# cslr_aif register map
Vendor: Texas Instruments
Registers are 32-bit, access per field, reset 0x0 unless marked. A register's access mark holds for its fields unless they carry their own. Offsets are as the file gives them; [hi:lo] are bit positions; {n}, {i} and the like mark numbered series; 'fields as' and 'values as' point back to an identical list.

## AIF (part 5 of 5) — High-speed interface for BTS antenna data
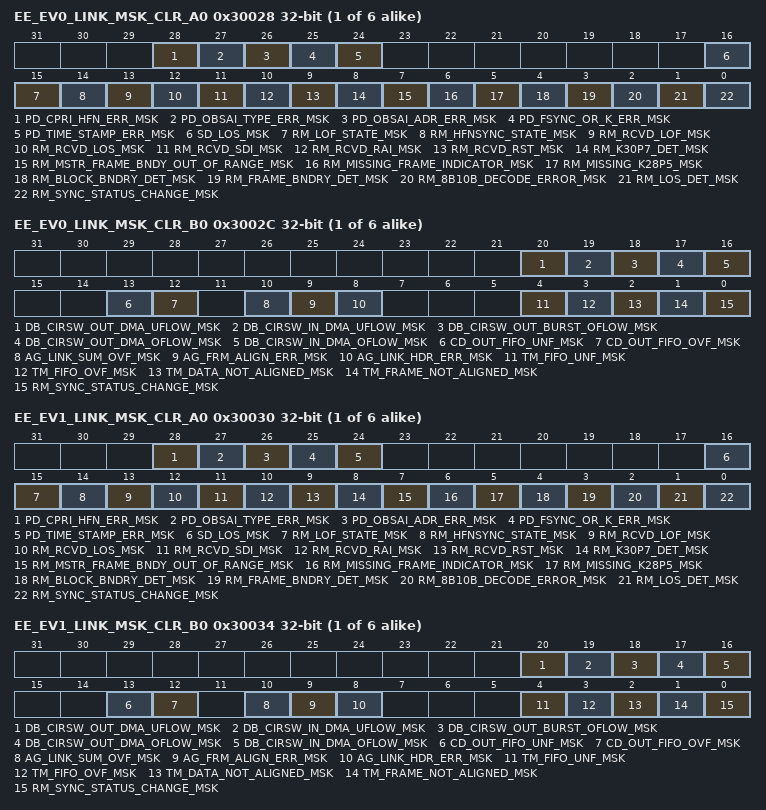
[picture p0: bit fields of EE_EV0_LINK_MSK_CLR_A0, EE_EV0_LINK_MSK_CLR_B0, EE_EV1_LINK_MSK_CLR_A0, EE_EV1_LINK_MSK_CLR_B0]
{0x30028+0x800*i} EE_EV0_LINK_MSK_CLR_A{i} (i=0..5) — Event 0 Link Interrupt Mask Clear Reg A
  [28] PD_CPRI_HFN_ERR_MSK rw — Mask for associated bit in the EE_EV0_LINK_ISM_A register. Writing this bit to a 1 clears the mask to 0 to disable the associated error/alarm. Reading this register returns the value of the mask bit.
  [27] PD_OBSAI_TYPE_ERR_MSK rw — Mask for associated bit in the EE_EV0_LINK_ISM_A register. Writing this bit to a 1 clears the mask to 0 to disable the associated error/alarm. Reading this register returns the value of the mask bit.
  [26] PD_OBSAI_ADR_ERR_MSK rw — Mask for associated bit in the EE_EV0_LINK_ISM_A register. Writing this bit to a 1 clears the mask to 0 to disable the associated error/alarm. Reading this register returns the value of the mask bit.
  [25] PD_FSYNC_OR_K_ERR_MSK rw — Mask for associated bit in the EE_EV0_LINK_ISM_A register. Writing this bit to a 1 clears the mask to 0 to disable the associated error/alarm. Reading this register returns the value of the mask bit.
  [24] PD_TIME_STAMP_ERR_MSK rw — Mask for associated bit in the EE_EV0_LINK_ISM_A register. Writing this bit to a 1 clears the mask to 0 to disable the associated error/alarm. Reading this register returns the value of the mask bit.
  [16] SD_LOS_MSK rw — Mask for associated bit in the EE_EV0_LINK_ISM_A register. Writing this bit to a 1 clears the mask to 0 to disable the associated error/alarm. Reading this register returns the value of the mask bit.
  [15] RM_LOF_STATE_MSK rw — Mask for associated bit in the EE_EV0_LINK_ISM_A register. Writing this bit to a 1 clears the mask to 0 to disable the associated error/alarm. Reading this register returns the value of the mask bit.
  [14] RM_HFNSYNC_STATE_MSK rw — Mask for associated bit in the EE_EV0_LINK_ISM_A register. Writing this bit to a 1 clears the mask to 0 to disable the associated error/alarm. Reading this register returns the value of the mask bit.
  [13] RM_RCVD_LOF_MSK rw — Mask for associated bit in the EE_EV0_LINK_ISM_A register. Writing this bit to a 1 clears the mask to 0 to disable the associated error/alarm. Reading this register returns the value of the mask bit.
  [12] RM_RCVD_LOS_MSK rw — Mask for associated bit in the EE_EV0_LINK_ISM_A register. Writing this bit to a 1 clears the mask to 0 to disable the associated error/alarm. Reading this register returns the value of the mask bit.
  [11] RM_RCVD_SDI_MSK rw — Mask for associated bit in the EE_EV0_LINK_ISM_A register. Writing this bit to a 1 clears the mask to 0 to disable the associated error/alarm. Reading this register returns the value of the mask bit.
  [10] RM_RCVD_RAI_MSK rw — Mask for associated bit in the EE_EV0_LINK_ISM_A register. Writing this bit to a 1 clears the mask to 0 to disable the associated error/alarm. Reading this register returns the value of the mask bit.
  [9] RM_RCVD_RST_MSK rw — Mask for associated bit in the EE_EV0_LINK_ISM_A register. Writing this bit to a 1 clears the mask to 0 to disable the associated error/alarm. Reading this register returns the value of the mask bit.
  [8] RM_K30P7_DET_MSK rw — Mask for associated bit in the EE_EV0_LINK_ISM_A register. Writing this bit to a 1 clears the mask to 0 to disable the associated error/alarm. Reading this register returns the value of the mask bit.
  [7] RM_MSTR_FRAME_BNDY_OUT_OF_RANGE_MSK rw — Mask for associated bit in the EE_EV0_LINK_ISM_A register. Writing this bit to a 1 clears the mask to 0 to disable the associated error/alarm. Reading this register returns the value of the mask bit.
  [6] RM_MISSING_FRAME_INDICATOR_MSK rw — Mask for associated bit in the EE_EV0_LINK_ISM_A register. Writing this bit to a 1 clears the mask to 0 to disable the associated error/alarm. Reading this register returns the value of the mask bit.
  [5] RM_MISSING_K28P5_MSK rw — Mask for associated bit in the EE_EV0_LINK_ISM_A register. Writing this bit to a 1 clears the mask to 0 to disable the associated error/alarm. Reading this register returns the value of the mask bit.
  [4] RM_BLOCK_BNDRY_DET_MSK rw — Mask for associated bit in the EE_EV0_LINK_ISM_A register. Writing this bit to a 1 clears the mask to 0 to disable the associated error/alarm. Reading this register returns the value of the mask bit.
  [3] RM_FRAME_BNDRY_DET_MSK rw — Mask for associated bit in the EE_EV0_LINK_ISM_A register. Writing this bit to a 1 clears the mask to 0 to disable the associated error/alarm. Reading this register returns the value of the mask bit.
  [2] RM_8B10B_DECODE_ERROR_MSK rw — Mask for associated bit in the EE_EV0_LINK_ISM_A register. Writing this bit to a 1 clears the mask to 0 to disable the associated error/alarm. Reading this register returns the value of the mask bit.
  [1] RM_LOS_DET_MSK rw — Mask for associated bit in the EE_EV0_LINK_ISM_A register. Writing this bit to a 1 clears the mask to 0 to disable the associated error/alarm. Reading this register returns the value of the mask bit.
  [0] RM_SYNC_STATUS_CHANGE_MSK rw — Mask for associated bit in the EE_EV0_LINK_ISM_A register. Writing this bit to a 1 clears the mask to 0 to disable the associated error/alarm. Reading this register returns the value of the mask bit.
{0x3002C+0x800*i} EE_EV0_LINK_MSK_CLR_B{i} (i=0..5) — Event 0 Link Interrupt Mask Clear Reg B
  [20] DB_CIRSW_OUT_DMA_UFLOW_MSK rw — Mask for associated bit in the EE_EV0_LINK_ISM_B register. Writing this bit to a 1 clears the mask to 0 to disable the associated error/alarm. Reading this register returns the value of the mask bit.
  [19] DB_CIRSW_IN_DMA_UFLOW_MSK rw — Mask for associated bit in the EE_EV0_LINK_ISM_B register. Writing this bit to a 1 clears the mask to 0 to disable the associated error/alarm. Reading this register returns the value of the mask bit.
  [18] DB_CIRSW_OUT_BURST_OFLOW_MSK rw — Mask for associated bit in the EE_EV0_LINK_ISM_B register. Writing this bit to a 1 clears the mask to 0 to disable the associated error/alarm. Reading this register returns the value of the mask bit.
  [17] DB_CIRSW_OUT_DMA_OFLOW_MSK rw — Mask for associated bit in the EE_EV0_LINK_ISM_B register. Writing this bit to a 1 clears the mask to 0 to disable the associated error/alarm. Reading this register returns the value of the mask bit.
  [16] DB_CIRSW_IN_DMA_OFLOW_MSK rw — Mask for associated bit in the EE_EV0_LINK_ISM_B register. Writing this bit to a 1 clears the mask to 0 to disable the associated error/alarm. Reading this register returns the value of the mask bit.
  [13] CD_OUT_FIFO_UNF_MSK rw — Mask for associated bit in the EE_EV0_LINK_ISM_B register. Writing this bit to a 1 clears the mask to 0 to disable the associated error/alarm. Reading this register returns the value of the mask bit.
  [12] CD_OUT_FIFO_OVF_MSK rw — Mask for associated bit in the EE_EV0_LINK_ISM_B register. Writing this bit to a 1 clears the mask to 0 to disable the associated error/alarm. Reading this register returns the value of the mask bit.
  [10] AG_LINK_SUM_OVF_MSK rw — Mask for associated bit in the EE_EV0_LINK_ISM_B register. Writing this bit to a 1 clears the mask to 0 to disable the associated error/alarm. Reading this register returns the value of the mask bit.
  [9] AG_FRM_ALIGN_ERR_MSK rw — Mask for associated bit in the EE_EV0_LINK_ISM_B register. Writing this bit to a 1 clears the mask to 0 to disable the associated error/alarm. Reading this register returns the value of the mask bit.
  [8] AG_LINK_HDR_ERR_MSK rw — Mask for associated bit in the EE_EV0_LINK_ISM_B register. Writing this bit to a 1 clears the mask to 0 to disable the associated error/alarm. Reading this register returns the value of the mask bit.
  [4] TM_FIFO_UNF_MSK rw — Mask for associated bit in the EE_EV0_LINK_ISM_B register. Writing this bit to a 1 clears the mask to 0 to disable the associated error/alarm. Reading this register returns the value of the mask bit.
  [3] TM_FIFO_OVF_MSK rw — Mask for associated bit in the EE_EV0_LINK_ISM_B register. Writing this bit to a 1 clears the mask to 0 to disable the associated error/alarm. Reading this register returns the value of the mask bit.
  [2] TM_DATA_NOT_ALIGNED_MSK rw — Mask for associated bit in the EE_EV0_LINK_ISM_B register. Writing this bit to a 1 clears the mask to 0 to disable the associated error/alarm. Reading this register returns the value of the mask bit.
  [1] TM_FRAME_NOT_ALIGNED_MSK rw — Mask for associated bit in the EE_EV0_LINK_ISM_B register. Writing this bit to a 1 clears the mask to 0 to disable the associated error/alarm. Reading this register returns the value of the mask bit.
  [0] RM_SYNC_STATUS_CHANGE_MSK rw — Mask for associated bit in the EE_EV0_LINK_ISM_B register. Writing this bit to a 1 clears the mask to 0 to disable the associated error/alarm. Reading this register returns the value of the mask bit.
{0x30030+0x800*i} EE_EV1_LINK_MSK_CLR_A{i} (i=0..5) — Event 1 Link Interrupt Mask Clear Reg A
  [28] PD_CPRI_HFN_ERR_MSK rw — Mask for associated bit in the EE_EV1_LINK_ISM_A register. Writing this bit to a 1 clears the mask to 0 to disable the associated error/alarm. Reading this register returns the value of the mask bit.
  [27] PD_OBSAI_TYPE_ERR_MSK rw — Mask for associated bit in the EE_EV1_LINK_ISM_A register. Writing this bit to a 1 clears the mask to 0 to disable the associated error/alarm. Reading this register returns the value of the mask bit.
  [26] PD_OBSAI_ADR_ERR_MSK rw — Mask for associated bit in the EE_EV1_LINK_ISM_A register. Writing this bit to a 1 clears the mask to 0 to disable the associated error/alarm. Reading this register returns the value of the mask bit.
  [25] PD_FSYNC_OR_K_ERR_MSK rw — Mask for associated bit in the EE_EV1_LINK_ISM_A register. Writing this bit to a 1 clears the mask to 0 to disable the associated error/alarm. Reading this register returns the value of the mask bit.
  [24] PD_TIME_STAMP_ERR_MSK rw — Mask for associated bit in the EE_EV1_LINK_ISM_A register. Writing this bit to a 1 clears the mask to 0 to disable the associated error/alarm. Reading this register returns the value of the mask bit.
  [16] SD_LOS_MSK rw — Mask for associated bit in the EE_EV1_LINK_ISM_A register. Writing this bit to a 1 clears the mask to 0 to disable the associated error/alarm. Reading this register returns the value of the mask bit.
  [15] RM_LOF_STATE_MSK rw — Mask for associated bit in the EE_EV1_LINK_ISM_A register. Writing this bit to a 1 clears the mask to 0 to disable the associated error/alarm. Reading this register returns the value of the mask bit.
  [14] RM_HFNSYNC_STATE_MSK rw — Mask for associated bit in the EE_EV1_LINK_ISM_A register. Writing this bit to a 1 clears the mask to 0 to disable the associated error/alarm. Reading this register returns the value of the mask bit.
  [13] RM_RCVD_LOF_MSK rw — Mask for associated bit in the EE_EV1_LINK_ISM_A register. Writing this bit to a 1 clears the mask to 0 to disable the associated error/alarm. Reading this register returns the value of the mask bit.
  [12] RM_RCVD_LOS_MSK rw — Mask for associated bit in the EE_EV1_LINK_ISM_A register. Writing this bit to a 1 clears the mask to 0 to disable the associated error/alarm. Reading this register returns the value of the mask bit.
  [11] RM_RCVD_SDI_MSK rw — Mask for associated bit in the EE_EV1_LINK_ISM_A register. Writing this bit to a 1 clears the mask to 0 to disable the associated error/alarm. Reading this register returns the value of the mask bit.
  [10] RM_RCVD_RAI_MSK rw — Mask for associated bit in the EE_EV1_LINK_ISM_A register. Writing this bit to a 1 clears the mask to 0 to disable the associated error/alarm. Reading this register returns the value of the mask bit.
  [9] RM_RCVD_RST_MSK rw — Mask for associated bit in the EE_EV1_LINK_ISM_A register. Writing this bit to a 1 clears the mask to 0 to disable the associated error/alarm. Reading this register returns the value of the mask bit.
  [8] RM_K30P7_DET_MSK rw — Mask for associated bit in the EE_EV1_LINK_ISM_A register. Writing this bit to a 1 clears the mask to 0 to disable the associated error/alarm. Reading this register returns the value of the mask bit.
  [7] RM_MSTR_FRAME_BNDY_OUT_OF_RANGE_MSK rw — Mask for associated bit in the EE_EV1_LINK_ISM_A register. Writing this bit to a 1 clears the mask to 0 to disable the associated error/alarm. Reading this register returns the value of the mask bit.
  [6] RM_MISSING_FRAME_INDICATOR_MSK rw — Mask for associated bit in the EE_EV1_LINK_ISM_A register. Writing this bit to a 1 clears the mask to 0 to disable the associated error/alarm. Reading this register returns the value of the mask bit.
  [5] RM_MISSING_K28P5_MSK rw — Mask for associated bit in the EE_EV1_LINK_ISM_A register. Writing this bit to a 1 clears the mask to 0 to disable the associated error/alarm. Reading this register returns the value of the mask bit.
  [4] RM_BLOCK_BNDRY_DET_MSK rw — Mask for associated bit in the EE_EV1_LINK_ISM_A register. Writing this bit to a 1 clears the mask to 0 to disable the associated error/alarm. Reading this register returns the value of the mask bit.
  [3] RM_FRAME_BNDRY_DET_MSK rw — Mask for associated bit in the EE_EV1_LINK_ISM_A register. Writing this bit to a 1 clears the mask to 0 to disable the associated error/alarm. Reading this register returns the value of the mask bit.
  [2] RM_8B10B_DECODE_ERROR_MSK rw — Mask for associated bit in the EE_EV1_LINK_ISM_A register. Writing this bit to a 1 clears the mask to 0 to disable the associated error/alarm. Reading this register returns the value of the mask bit.
  [1] RM_LOS_DET_MSK rw — Mask for associated bit in the EE_EV1_LINK_ISM_A register. Writing this bit to a 1 clears the mask to 0 to disable the associated error/alarm. Reading this register returns the value of the mask bit.
  [0] RM_SYNC_STATUS_CHANGE_MSK rw — Mask for associated bit in the EE_EV1_LINK_ISM_A register. Writing this bit to a 1 clears the mask to 0 to disable the associated error/alarm. Reading this register returns the value of the mask bit.
{0x30034+0x800*i} EE_EV1_LINK_MSK_CLR_B{i} (i=0..5) — Event 1 Link Interrupt Mask Clear Reg B
  [20] DB_CIRSW_OUT_DMA_UFLOW_MSK rw — Mask for associated bit in the EE_EV1_LINK_ISM_B register. Writing this bit to a 1 clears the mask to 0 to disable the associated error/alarm. Reading this register returns the value of the mask bit.
  [19] DB_CIRSW_IN_DMA_UFLOW_MSK rw — Mask for associated bit in the EE_EV1_LINK_ISM_B register. Writing this bit to a 1 clears the mask to 0 to disable the associated error/alarm. Reading this register returns the value of the mask bit.
  [18] DB_CIRSW_OUT_BURST_OFLOW_MSK rw — Mask for associated bit in the EE_EV1_LINK_ISM_B register. Writing this bit to a 1 clears the mask to 0 to disable the associated error/alarm. Reading this register returns the value of the mask bit.
  [17] DB_CIRSW_OUT_DMA_OFLOW_MSK rw — Mask for associated bit in the EE_EV1_LINK_ISM_B register. Writing this bit to a 1 clears the mask to 0 to disable the associated error/alarm. Reading this register returns the value of the mask bit.
  [16] DB_CIRSW_IN_DMA_OFLOW_MSK rw — Mask for associated bit in the EE_EV1_LINK_ISM_B register. Writing this bit to a 1 clears the mask to 0 to disable the associated error/alarm. Reading this register returns the value of the mask bit.
  [13] CD_OUT_FIFO_UNF_MSK rw — Mask for associated bit in the EE_EV1_LINK_ISM_B register. Writing this bit to a 1 clears the mask to 0 to disable the associated error/alarm. Reading this register returns the value of the mask bit.
  [12] CD_OUT_FIFO_OVF_MSK rw — Mask for associated bit in the EE_EV1_LINK_ISM_B register. Writing this bit to a 1 clears the mask to 0 to disable the associated error/alarm. Reading this register returns the value of the mask bit.
  [10] AG_LINK_SUM_OVF_MSK rw — Mask for associated bit in the EE_EV1_LINK_ISM_B register. Writing this bit to a 1 clears the mask to 0 to disable the associated error/alarm. Reading this register returns the value of the mask bit.
  [9] AG_FRM_ALIGN_ERR_MSK rw — Mask for associated bit in the EE_EV1_LINK_ISM_B register. Writing this bit to a 1 clears the mask to 0 to disable the associated error/alarm. Reading this register returns the value of the mask bit.
  [8] AG_LINK_HDR_ERR_MSK rw — Mask for associated bit in the EE_EV1_LINK_ISM_B register. Writing this bit to a 1 clears the mask to 0 to disable the associated error/alarm. Reading this register returns the value of the mask bit.
  [4] TM_FIFO_UNF_MSK rw — Mask for associated bit in the EE_EV1_LINK_ISM_B register. Writing this bit to a 1 clears the mask to 0 to disable the associated error/alarm. Reading this register returns the value of the mask bit.
  [3] TM_FIFO_OVF_MSK rw — Mask for associated bit in the EE_EV1_LINK_ISM_B register. Writing this bit to a 1 clears the mask to 0 to disable the associated error/alarm. Reading this register returns the value of the mask bit.
  [2] TM_DATA_NOT_ALIGNED_MSK rw — Mask for associated bit in the EE_EV1_LINK_ISM_B register. Writing this bit to a 1 clears the mask to 0 to disable the associated error/alarm. Reading this register returns the value of the mask bit.
  [1] TM_FRAME_NOT_ALIGNED_MSK rw — Mask for associated bit in the EE_EV1_LINK_ISM_B register. Writing this bit to a 1 clears the mask to 0 to disable the associated error/alarm. Reading this register returns the value of the mask bit.
  [0] RM_SYNC_STATUS_CHANGE_MSK rw — Mask for associated bit in the EE_EV1_LINK_ISM_B register. Writing this bit to a 1 clears the mask to 0 to disable the associated error/alarm. Reading this register returns the value of the mask bit.
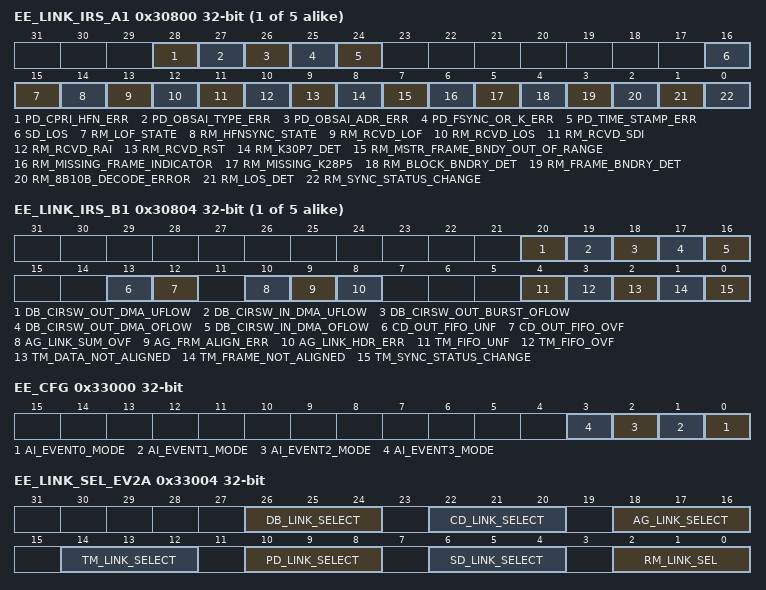
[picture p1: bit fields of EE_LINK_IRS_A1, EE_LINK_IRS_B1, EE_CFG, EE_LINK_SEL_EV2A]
{0x30000+0x800*i} EE_LINK_IRS_A{i} (i=1..5) — Event Enable Link Interrupt Source Raw Status Register A
  [28] PD_CPRI_HFN_ERR rw — CPRI hyper frame number different than FSM expected
  [27] PD_OBSAI_TYPE_ERR rw — OBSAI header type look up resulted in illegal type
  [26] PD_OBSAI_ADR_ERR rw — OBSAI header address look up resulted in illegal address
  [25] PD_FSYNC_OR_K_ERR rw — Frame sync or K character different than FSM expected
  [24] PD_TIME_STAMP_ERR rw — OBSAI time stamp error
  [16] SD_LOS rw — Loss of signal condition
  [15] RM_LOF_STATE rw — CPRI receiver entered State 0 or State 1
  [14] RM_HFNSYNC_STATE rw — CPRI receiver in FSM State 3
  [13] RM_RCVD_LOF rw — Received lof (Z.130.0, b4) (CPRI only)
  [12] RM_RCVD_LOS rw — Received los (Z.130.0, b3) (CPRI only)
  [11] RM_RCVD_SDI rw — Received sdi (Z.130.0, b2) (CPRI only)
  [10] RM_RCVD_RAI rw — Received rai (Z.130.0, b1) (CPRI only)
  [9] RM_RCVD_RST rw — Received reset (Z.130.0, b0) (CPRI only)
  [8] RM_K30P7_DET rw — Indicates that a K30.7 character was received (OBSAI only).
  [7] RM_MSTR_FRAME_BNDY_OUT_OF_RANGE rw — This error is indicated when received Master Frame is detected outside the programmable window valid_mstr_frame_wind (typically 65ns)
  [6] RM_MISSING_FRAME_INDICATOR rw — Indicates that a K28.7 (OBSAI) or a K28.5 (CPRI) character was missing and assumes receiver is in state ST3
  [5] RM_MISSING_K28P5 rw — Indicates that a K28.5 characters was missing (OBSAI only and assumes receiver is in frame sync state ST3.
  [4] RM_BLOCK_BNDRY_DET rw — Block boundary (OBSAI) is detected or at a Hyperframe boundary (CPRI)
  [3] RM_FRAME_BNDRY_DET rw — Master frame boundary (OBSAI) is detected or at a Hyperframe boundary (CPRI) that delimits a UMTS frame
  [2] RM_8B10B_DECODE_ERROR rw — 8b10b error has occurred.
  [1] RM_LOS_DET rw — los_thold is reached
  [0] RM_SYNC_STATUS_CHANGE rw — Indicates the status of the rx state machine.
{0x30004+0x800*i} EE_LINK_IRS_B{i} (i=1..5) — Event Enable Link Interrupt Source Raw Status Register B
  [20] DB_CIRSW_OUT_DMA_UFLOW rw — Circuit Switch RAM Outbound DMA underflow
  [19] DB_CIRSW_IN_DMA_UFLOW rw — Circuit Switch RAM Inbound DMA underflow
  [18] DB_CIRSW_OUT_BURST_OFLOW rw — Circuit Switch RAM Outbound RAM burst strobe overflow
  [17] DB_CIRSW_OUT_DMA_OFLOW rw — Circuit Switch RAM Outbound DMA overflow
  [16] DB_CIRSW_IN_DMA_OFLOW rw — Circuit Switch RAM Inbound DMA overflow
  [13] CD_OUT_FIFO_UNF rw — Output FIFO underflow
  [12] CD_OUT_FIFO_OVF rw — Output FIFO overflow
  [10] AG_LINK_SUM_OVF rw — Summation overflow on any AxC
  [9] AG_FRM_ALIGN_ERR rw — Frame alignment error between PE and CD
  [8] AG_LINK_HDR_ERR rw — Link header error on any message slot
  [4] TM_FIFO_UNF rw — TX MAC FIFO Underflow flag
  [3] TM_FIFO_OVF rw — TX MAC FIFO Overflow flag
  [2] TM_DATA_NOT_ALIGNED rw — This error is indicated when data to be transmitted is detected as not aligned with Master Frame + delta_offset (i.e. Frame boundary to be transmitted is not aligned with frame boundary received internally)
  [1] TM_FRAME_NOT_ALIGNED rw — This error is indicated when the frame strobe from the Frame Sync Module is not aligned with Master Frame + delta_offset.
  [0] TM_SYNC_STATUS_CHANGE rw — Indicates a change of tx state machine state
0x33000 EE_CFG — Exception Event Configuration Register
  [all] fields
    0=ERROR_MODE; 1=TRIGGER_MODE
  [n] AI_EVENT{n}_MODE rw (n=0..3)
0x33004 EE_LINK_SEL_EV2A — Exception Event AI_EVENT[2] Link Select Register A
  [all] fields
    {v}=LINK{v} (v=0..5)
  [26:24] DB_LINK_SELECT rw — Link select for DB error/alarms aggregated to ai_event[2]. See rm_link_sel for encodings.
  [22:20] CD_LINK_SELECT rw — Link select for CD error/alarms aggregated to ai_event[2]. See rm_link_sel for encodings.
  [18:16] AG_LINK_SELECT rw — Link select for AG error/alarms aggregated to ai_event[2]. See rm_link_sel for encodings.
  [14:12] TM_LINK_SELECT rw — Link select for TM error/alarms aggregated to ai_event[2]. See rm_link_sel for encodings.
  [10:8] PD_LINK_SELECT rw — Link select for PD error/alarms aggregated to ai_event[2]. See rm_link_sel for encodings.
  [6:4] SD_LINK_SELECT rw — Link select for SD error/alarms aggregated to ai_event[2]. See rm_link_sel for encodings.
  [2:0] RM_LINK_SEL rw — Link select for RM error/alarms aggregated to ai_event[2]:
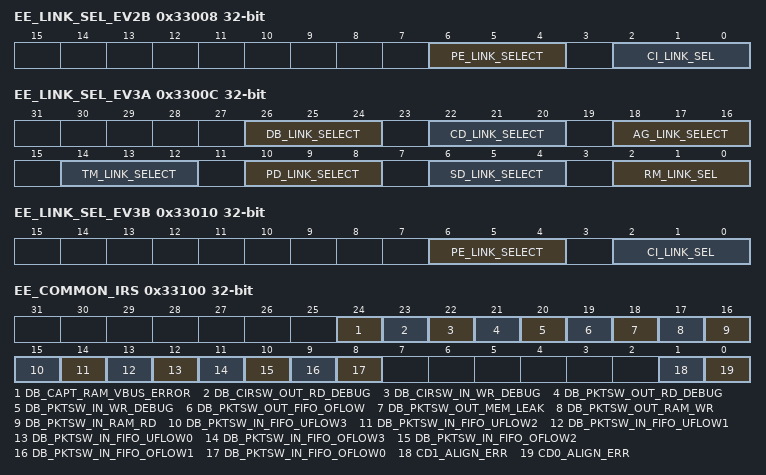
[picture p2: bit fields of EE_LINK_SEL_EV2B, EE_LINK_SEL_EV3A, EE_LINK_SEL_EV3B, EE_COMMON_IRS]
0x33008 EE_LINK_SEL_EV2B — Exception Event AI_EVENT[2] Link Select Register B
  [6:4] PE_LINK_SELECT rw — Link select for PE error/alarms aggregated to ai_event[2]. See rm_link_sel for encodings.
    {v}=LINK{v} (v=0..5)
  [2:0] CI_LINK_SEL rw — Link select for CI error/alarms aggregated to ai_event[2]:
    {v}=LINK{v} (v=0..5)
0x3300C EE_LINK_SEL_EV3A — Exception Event AI_EVENT[3] Link Select Register A
  fields as EE_LINK_SEL_EV2A
0x33010 EE_LINK_SEL_EV3B — Exception Event AI_EVENT[3] Link Select Register B
  fields as EE_LINK_SEL_EV2B
0x33014 EE_INT_END — Exception Event End of Interrupt Register
  [1:0] INTR_EOI rw — Whenever this register is written, the ai_event[3:0] signal addressed by this field is allowed to generate another event if the any aggregated bits in the associated Interrupt Source Masked Status Registers are set to a 1. This field is ignored if the associated ai_eventX_mode bit in Table 102 is set to "trigger mode".
    {v}=AI_EVT{v} (v=0..3)
0x33080 EE_AI_RUN ro — Event Enable AI Runing Register
  [0] RUN_STAT — AI Running Status
    0=NOT_RUNNING (AI is not operating normally); 1=RUNNING (AI is operating normally)
0x33100 EE_COMMON_IRS — Event Enable Common Interrupt Source Raw Status Register
  [24] DB_CAPT_RAM_VBUS_ERROR rw — Capture buffer, dma reading wrong/wr half of RAM
  [23] DB_CIRSW_OUT_RD_DEBUG rw — Circuit Switched Outbound RAM VBUS read (OK for offline debug and delayed streams)
  [22] DB_CIRSW_IN_WR_DEBUG rw — Circuit Switched Inbound RAM VBUS write (OK for offline debug)
  [21] DB_PKTSW_OUT_RD_DEBUG rw — Packet Switched Outbound RAM VBUS read (OK for offline debug)
  [20] DB_PKTSW_IN_WR_DEBUG rw — Packet Switched Inbound RAM VBUS write (OK for offline debug)
  [19] DB_PKTSW_OUT_FIFO_OFLOW rw — Packet Switched Outbound RAM/FIFO overflow write pointer wrap into read
  [18] DB_PKTSW_OUT_MEM_LEAK rw — Packet Switched Outbound RAM/FIFO linked list error
  [17] DB_PKTSW_OUT_RAM_WR rw — Packet Switched Outbound RAM wr (OBSAI only; OK for CPRI)
  [16] DB_PKTSW_IN_RAM_RD rw — Packet Switched Inbound RAM rd (OBSAI only; OK for CPRI)
  [15] DB_PKTSW_IN_FIFO_UFLOW3 rw — Packet Switched Error FIFO DMA Underflow
  [14] DB_PKTSW_IN_FIFO_UFLOW2 rw — Packet Switched Inbound RAM/FIFO #2 DMA Underflow
  [13] DB_PKTSW_IN_FIFO_UFLOW1 rw — Packet Switched Inbound RAM/FIFO #1 DMA Underflow
  [12] DB_PKTSW_IN_FIFO_UFLOW0 rw — Packet Switched Inbound RAM/FIFO #0 DMA Underflow
  [11] DB_PKTSW_IN_FIFO_OFLOW3 rw — Packet Switched Error FIFO DMA Overflow
  [10] DB_PKTSW_IN_FIFO_OFLOW2 rw — Packet Switched Inbound RAM/FIFO #2 DMA Overflow
  [9] DB_PKTSW_IN_FIFO_OFLOW1 rw — Packet Switched Inbound RAM/FIFO #1 DMA Overflow
  [8] DB_PKTSW_IN_FIFO_OFLOW0 rw — Packet Switched Inbound RAM/FIFO #0 DMA Overflow
  [1] CD1_ALIGN_ERR rw — RM inputs not aligned to CD #1
  [0] CD0_ALIGN_ERR rw — RM inputs not aligned to CD #0
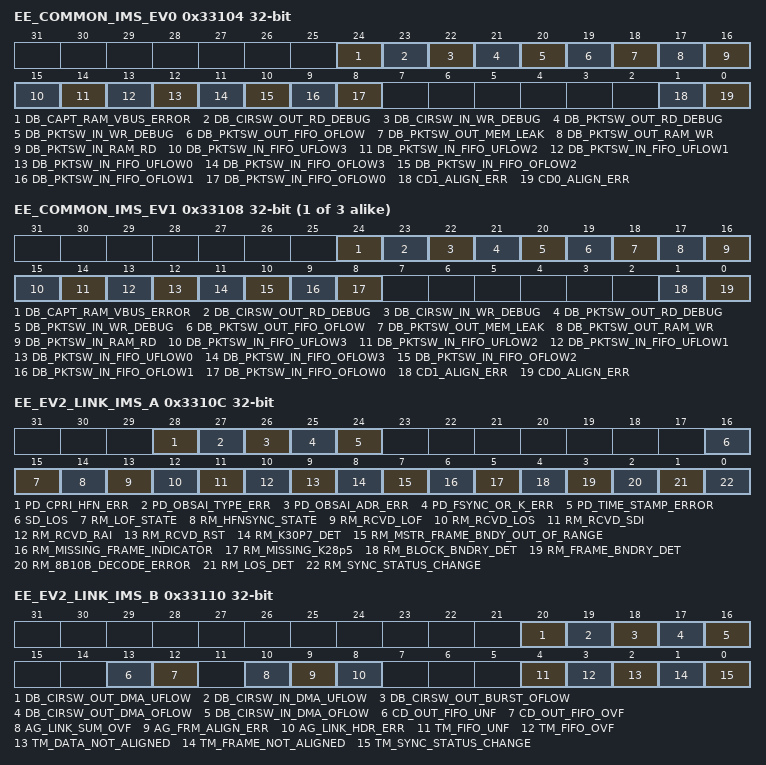
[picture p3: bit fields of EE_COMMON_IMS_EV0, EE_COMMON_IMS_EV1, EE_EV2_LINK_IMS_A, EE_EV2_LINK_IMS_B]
0x33104 EE_COMMON_IMS_EV0 — Event Enable Common Interrupt Event 0 Masked Status Register
  fields as EE_COMMON_IRS
{0x330FC+0xC*i} EE_COMMON_IMS_EV{i} (i=1..3) — Event Enable Common Interrupt Event {i} Masked Status Register
  fields as EE_COMMON_IRS
0x3310C EE_EV2_LINK_IMS_A — Event Enable Event 2 Interrupt Source Masked Status Reg A
  [28] PD_CPRI_HFN_ERR rw — CPRI hyper frame number different than FSM expected
  [27] PD_OBSAI_TYPE_ERR rw — OBSAI header type look up resulted in illegal type
  [26] PD_OBSAI_ADR_ERR rw — OBSAI header address look up resulted in illegal address
  [25] PD_FSYNC_OR_K_ERR rw — Frame sync or K character different than FSM expected
  [24] PD_TIME_STAMP_ERROR rw — OBSAI time stamp error
  [16] SD_LOS rw — Loss of signal condition
  [15] RM_LOF_STATE rw — CPRI receiver entered State 0 or State 1
  [14] RM_HFNSYNC_STATE rw — CPRI receiver in FSM State 3
  [13] RM_RCVD_LOF rw — Received lof (Z.130.0, b4) (CPRI only)
  [12] RM_RCVD_LOS rw — Received los (Z.130.0, b3) (CPRI only)
  [11] RM_RCVD_SDI rw — Received sdi (Z.130.0, b2) (CPRI only)
  [10] RM_RCVD_RAI rw — Received rai (Z.130.0, b1) (CPRI only)
  [9] RM_RCVD_RST rw — Received reset (Z.130.0, b0) (CPRI only)
  [8] RM_K30P7_DET rw — Indicates that a K30.7 character was detected (OBSAI only).
  [7] RM_MSTR_FRAME_BNDY_OUT_OF_RANGE rw — This error is indicated when received Master Frame is detected outside the programmable window valid_mstr_frame_wind (typically 65ns)
  [6] RM_MISSING_FRAME_INDICATOR rw — Indicates that a K28.7 (OBSAI) or a K28.5 (CPRI) character was missing and assumes receiver is in state ST3
  [5] RM_MISSING_K28p5 rw — Indicates that a K28.5 characters was missing (OBSAI only and assumes receiver is in frame sync state ST3.
  [4] RM_BLOCK_BNDRY_DET rw — Block boundary (OBSAI) is detected or at a Hyperframe boundary (CPRI)
  [3] RM_FRAME_BNDRY_DET rw — Master frame boundary (OBSAI) is detected or at a Hyperframe boundary (CPRI) that delimits a UMTS frame
  [2] RM_8B10B_DECODE_ERROR rw — 8b10b error has occurred.
  [1] RM_LOS_DET rw — los_thold is reached
  [0] RM_SYNC_STATUS_CHANGE rw — Indicates the status of the rx state machine.
0x33110 EE_EV2_LINK_IMS_B — Event Enable Event 2 Interrupt Source Masked Status Reg B
  fields as EE_LINK_IRS_B1
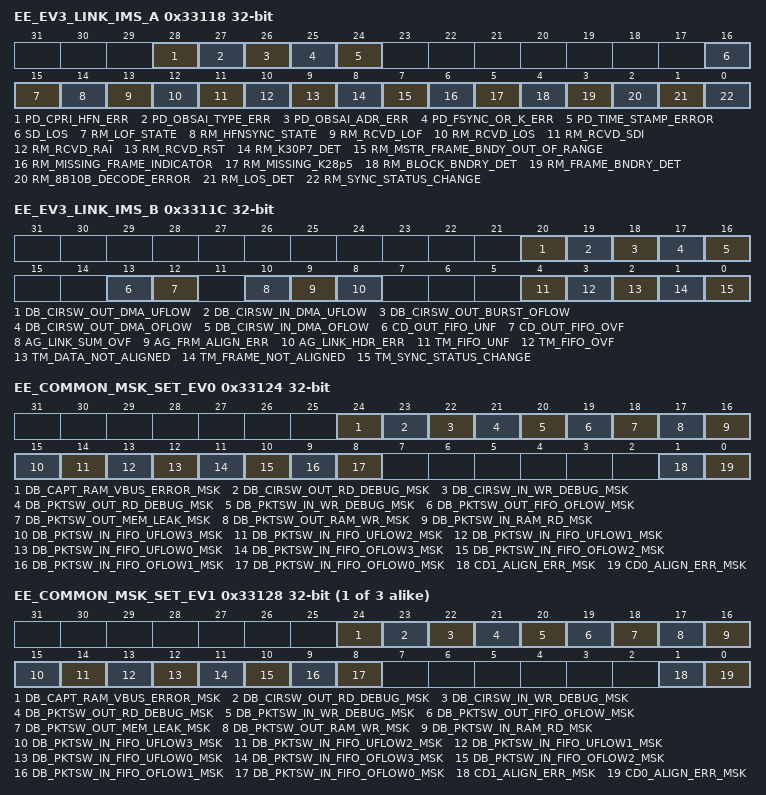
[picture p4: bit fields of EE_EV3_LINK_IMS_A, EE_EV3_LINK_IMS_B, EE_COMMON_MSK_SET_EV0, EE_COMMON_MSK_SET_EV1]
0x33118 EE_EV3_LINK_IMS_A — Event Enable Event 3 Interrupt Source Masked Status Reg A
  fields as EE_EV2_LINK_IMS_A
0x3311C EE_EV3_LINK_IMS_B — Event Enable Event 3 Interrupt Source Masked Status Reg B
  fields as EE_LINK_IRS_B1
0x33124 EE_COMMON_MSK_SET_EV0 — Event Enable 0 Common Interrupt Mask Set Register
  [24] DB_CAPT_RAM_VBUS_ERROR_MSK rw — Capture buffer, dma reading wrong/wr half of RAM
  [23] DB_CIRSW_OUT_RD_DEBUG_MSK rw — Circuit Switched Outbound RAM VBUS read (OK for offline debug and delayed streams)
  [22] DB_CIRSW_IN_WR_DEBUG_MSK rw — Circuit Switched Inbound RAM VBUS write (OK for offline debug)
  [21] DB_PKTSW_OUT_RD_DEBUG_MSK rw — Packet Switched Outbound RAM VBUS read (OK for offline debug)
  [20] DB_PKTSW_IN_WR_DEBUG_MSK rw — Packet Switched Inbound RAM VBUS write (OK for offline debug)
  [19] DB_PKTSW_OUT_FIFO_OFLOW_MSK rw — Packet Switched Outbound RAM/FIFO overflow write pointer wrap into read
  [18] DB_PKTSW_OUT_MEM_LEAK_MSK rw — Packet Switched Outbound RAM/FIFO linked list error
  [17] DB_PKTSW_OUT_RAM_WR_MSK rw — Packet Switched Outbound RAM wr (OBSAI only; OK for CPRI)
  [16] DB_PKTSW_IN_RAM_RD_MSK rw — Packet Switched Inbound RAM rd (OBSAI only; OK for CPRI)
  [15] DB_PKTSW_IN_FIFO_UFLOW3_MSK rw — Packet Switched Error FIFO DMA Underflow
  [14] DB_PKTSW_IN_FIFO_UFLOW2_MSK rw — Packet Switched Inbound RAM/FIFO #2 DMA Underflow
  [13] DB_PKTSW_IN_FIFO_UFLOW1_MSK rw — Packet Switched Inbound RAM/FIFO #1 DMA Underflow
  [12] DB_PKTSW_IN_FIFO_UFLOW0_MSK rw — Packet Switched Inbound RAM/FIFO #0 DMA Underflow
  [11] DB_PKTSW_IN_FIFO_OFLOW3_MSK rw — Packet Switched Error FIFO DMA Overflow
  [10] DB_PKTSW_IN_FIFO_OFLOW2_MSK rw — Packet Switched Inbound RAM/FIFO #2 DMA Overflow
  [9] DB_PKTSW_IN_FIFO_OFLOW1_MSK rw — Packet Switched Inbound RAM/FIFO #1 DMA Overflow
  [8] DB_PKTSW_IN_FIFO_OFLOW0_MSK rw — Packet Switched Inbound RAM/FIFO #0 DMA Overflow
  [1] CD1_ALIGN_ERR_MSK rw — RM inputs not aligned to CD #1
  [0] CD0_ALIGN_ERR_MSK rw — RM inputs not aligned to CD #0
{0x3311C+0xC*i} EE_COMMON_MSK_SET_EV{i} (i=1..3) — Event Enable {i} Common Interrupt Mask Set Register
  fields as EE_COMMON_MSK_SET_EV0
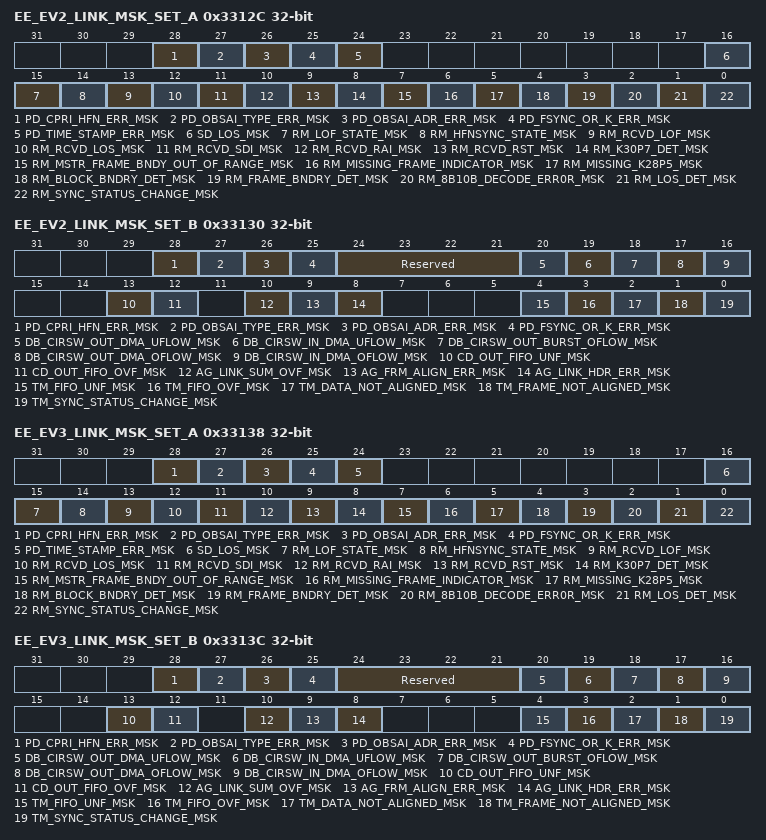
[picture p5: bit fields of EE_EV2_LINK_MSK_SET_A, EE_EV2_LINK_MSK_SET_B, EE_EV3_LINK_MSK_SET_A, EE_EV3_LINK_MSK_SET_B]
0x3312C EE_EV2_LINK_MSK_SET_A — Event 2 Link Interrupt Source Mask Set Reg A
  [28] PD_CPRI_HFN_ERR_MSK rw — Mask for associated bit in the EE_EV0_LINK_ISM_A register. Writing this bit to a 1 sets the mask to 1 to enable the associated error/alarm. Reading this register returns the value of the mask bit.
  [27] PD_OBSAI_TYPE_ERR_MSK rw — Mask for associated bit in the EE_EV0_LINK_ISM_A register. Writing this bit to a 1 sets the mask to 1 to enable the associated error/alarm. Reading this register returns the value of the mask bit.
  [26] PD_OBSAI_ADR_ERR_MSK rw — Mask for associated bit in the EE_EV0_LINK_ISM_A register. Writing this bit to a 1 sets the mask to 1 to enable the associated error/alarm. Reading this register returns the value of the mask bit.
  [25] PD_FSYNC_OR_K_ERR_MSK rw — Mask for associated bit in the EE_EV0_LINK_ISM_A register. Writing this bit to a 1 sets the mask to 1 to enable the associated error/alarm. Reading this register returns the value of the mask bit.
  [24] PD_TIME_STAMP_ERR_MSK rw — Mask for associated bit in the EE_EV0_LINK_ISM_A register. Writing this bit to a 1 sets the mask to 1 to enable the associated error/alarm. Reading this register returns the value of the mask bit.
  [16] SD_LOS_MSK rw — Mask for associated bit in the EE_EV0_LINK_ISM_A register. Writing this bit to a 1 sets the mask to 1 to enable the associated error/alarm. Reading this register returns the value of the mask bit.
  [15] RM_LOF_STATE_MSK rw — Mask for associated bit in the EE_EV0_LINK_ISM_A register. Writing this bit to a 1 sets the mask to 1 to enable the associated error/alarm. Reading this register returns the value of the mask bit.
  [14] RM_HFNSYNC_STATE_MSK rw — Mask for associated bit in the EE_EV0_LINK_ISM_A register. Writing this bit to a 1 sets the mask to 1 to enable the associated error/alarm. Reading this register returns the value of the mask bit.
  [13] RM_RCVD_LOF_MSK rw — Mask for associated bit in the EE_EV0_LINK_ISM_A register. Writing this bit to a 1 sets the mask to 1 to enable the associated error/alarm. Reading this register returns the value of the mask bit.
  [12] RM_RCVD_LOS_MSK rw — Mask for associated bit in the EE_EV0_LINK_ISM_A register. Writing this bit to a 1 sets the mask to 1 to enable the associated error/alarm. Reading this register returns the value of the mask bit.
  [11] RM_RCVD_SDI_MSK rw — Mask for associated bit in the EE_EV0_LINK_ISM_A register. Writing this bit to a 1 sets the mask to 1 to enable the associated error/alarm. Reading this register returns the value of the mask bit.
  [10] RM_RCVD_RAI_MSK rw — Mask for associated bit in the EE_EV0_LINK_ISM_A register. Writing this bit to a 1 sets the mask to 1 to enable the associated error/alarm. Reading this register returns the value of the mask bit.
  [9] RM_RCVD_RST_MSK rw — Mask for associated bit in the EE_EV0_LINK_ISM_A register. Writing this bit to a 1 sets the mask to 1 to enable the associated error/alarm. Reading this register returns the value of the mask bit.
  [8] RM_K30P7_DET_MSK rw — Mask for associated bit in the EE_EV0_LINK_ISM_A register. Writing this bit to a 1 sets the mask to 1 to enable the associated error/alarm. Reading this register returns the value of the mask bit.
  [7] RM_MSTR_FRAME_BNDY_OUT_OF_RANGE_MSK rw — Mask for associated bit in the EE_EV0_LINK_ISM_A register. Writing this bit to a 1 sets the mask to 1 to enable the associated error/alarm. Reading this register returns the value of the mask bit.
  [6] RM_MISSING_FRAME_INDICATOR_MSK rw — Mask for associated bit in the EE_EV0_LINK_ISM_A register. Writing this bit to a 1 sets the mask to 1 to enable the associated error/alarm. Reading this register returns the value of the mask bit.
  [5] RM_MISSING_K28P5_MSK rw — Mask for associated bit in the EE_EV0_LINK_ISM_A register. Writing this bit to a 1 sets the mask to 1 to enable the associated error/alarm. Reading this register returns the value of the mask bit.
  [4] RM_BLOCK_BNDRY_DET_MSK rw — Mask for associated bit in the EE_EV0_LINK_ISM_A register. Writing this bit to a 1 sets the mask to 1 to enable the associated error/alarm. Reading this register returns the value of the mask bit.
  [3] RM_FRAME_BNDRY_DET_MSK rw — Mask for associated bit in the EE_EV0_LINK_ISM_A register. Writing this bit to a 1 sets the mask to 1 to enable the associated error/alarm. Reading this register returns the value of the mask bit.
  [2] RM_8B10B_DECODE_ERR0R_MSK rw — Mask for associated bit in the EE_EV0_LINK_ISM_A register. Writing this bit to a 1 sets the mask to 1 to enable the associated error/alarm. Reading this register returns the value of the mask bit.
  [1] RM_LOS_DET_MSK rw — Mask for associated bit in the EE_EV0_LINK_ISM_A register. Writing this bit to a 1 sets the mask to 1 to enable the associated error/alarm. Reading this register returns the value of the mask bit.
  [0] RM_SYNC_STATUS_CHANGE_MSK rw — Mask for associated bit in the EE_EV0_LINK_ISM_A register. Writing this bit to a 1 sets the mask to 1 to enable the associated error/alarm. Reading this register returns the value of the mask bit.
0x33130 EE_EV2_LINK_MSK_SET_B access not given — Event 2 Link Interrupt Source Mask Set Reg B
  [28] PD_CPRI_HFN_ERR_MSK rw — Mask for associated bit in the EE_EV0_LINK_ISM_A register. Writing this bit to a 1 sets the mask to 1 to enable the associated error/alarm. Reading this register returns the value of the mask bit.
  [27] PD_OBSAI_TYPE_ERR_MSK rw — Mask for associated bit in the EE_EV0_LINK_ISM_A register. Writing this bit to a 1 sets the mask to 1 to enable the associated error/alarm. Reading this register returns the value of the mask bit.
  [26] PD_OBSAI_ADR_ERR_MSK rw — Mask for associated bit in the EE_EV0_LINK_ISM_A register. Writing this bit to a 1 sets the mask to 1 to enable the associated error/alarm. Reading this register returns the value of the mask bit.
  [25] PD_FSYNC_OR_K_ERR_MSK rw — Mask for associated bit in the EE_EV0_LINK_ISM_A register. Writing this bit to a 1 sets the mask to 1 to enable the associated error/alarm. Reading this register returns the value of the mask bit.
  [24:21] Reserved — (access N)
  [20] DB_CIRSW_OUT_DMA_UFLOW_MSK rw — Mask for associated bit in the EE_EV0_LINK_ISM_A register. Writing this bit to a 1 sets the mask to 1 to enable the associated error/alarm. Reading this register returns the value of the mask bit.
  [19] DB_CIRSW_IN_DMA_UFLOW_MSK rw — Mask for associated bit in the EE_EV0_LINK_ISM_A register. Writing this bit to a 1 sets the mask to 1 to enable the associated error/alarm. Reading this register returns the value of the mask bit.
  [18] DB_CIRSW_OUT_BURST_OFLOW_MSK rw — Mask for associated bit in the EE_EV0_LINK_ISM_A register. Writing this bit to a 1 sets the mask to 1 to enable the associated error/alarm. Reading this register returns the value of the mask bit.
  [17] DB_CIRSW_OUT_DMA_OFLOW_MSK rw — Mask for associated bit in the EE_EV0_LINK_ISM_A register. Writing this bit to a 1 sets the mask to 1 to enable the associated error/alarm. Reading this register returns the value of the mask bit.
  [16] DB_CIRSW_IN_DMA_OFLOW_MSK rw — Mask for associated bit in the EE_EV0_LINK_ISM_A register. Writing this bit to a 1 sets the mask to 1 to enable the associated error/alarm. Reading this register returns the value of the mask bit.
  [13] CD_OUT_FIFO_UNF_MSK rw — Mask for associated bit in the EE_EV0_LINK_ISM_A register. Writing this bit to a 1 sets the mask to 1 to enable the associated error/alarm. Reading this register returns the value of the mask bit.
  [12] CD_OUT_FIFO_OVF_MSK rw — Mask for associated bit in the EE_EV0_LINK_ISM_A register. Writing this bit to a 1 sets the mask to 1 to enable the associated error/alarm. Reading this register returns the value of the mask bit.
  [10] AG_LINK_SUM_OVF_MSK rw — Mask for associated bit in the EE_EV0_LINK_ISM_A register. Writing this bit to a 1 sets the mask to 1 to enable the associated error/alarm. Reading this register returns the value of the mask bit.
  [9] AG_FRM_ALIGN_ERR_MSK rw — Mask for associated bit in the EE_EV0_LINK_ISM_A register. Writing this bit to a 1 sets the mask to 1 to enable the associated error/alarm. Reading this register returns the value of the mask bit.
  [8] AG_LINK_HDR_ERR_MSK rw — Mask for associated bit in the EE_EV0_LINK_ISM_A register. Writing this bit to a 1 sets the mask to 1 to enable the associated error/alarm. Reading this register returns the value of the mask bit.
  [4] TM_FIFO_UNF_MSK rw — Mask for associated bit in the EE_EV0_LINK_ISM_A register. Writing this bit to a 1 sets the mask to 1 to enable the associated error/alarm. Reading this register returns the value of the mask bit.
  [3] TM_FIFO_OVF_MSK rw — Mask for associated bit in the EE_EV0_LINK_ISM_A register. Writing this bit to a 1 sets the mask to 1 to enable the associated error/alarm. Reading this register returns the value of the mask bit.
  [2] TM_DATA_NOT_ALIGNED_MSK rw — Mask for associated bit in the EE_EV0_LINK_ISM_A register. Writing this bit to a 1 sets the mask to 1 to enable the associated error/alarm. Reading this register returns the value of the mask bit.
  [1] TM_FRAME_NOT_ALIGNED_MSK rw — Mask for associated bit in the EE_EV0_LINK_ISM_A register. Writing this bit to a 1 sets the mask to 1 to enable the associated error/alarm. Reading this register returns the value of the mask bit.
  [0] TM_SYNC_STATUS_CHANGE_MSK rw — Mask for associated bit in the EE_EV0_LINK_ISM_A register. Writing this bit to a 1 sets the mask to 1 to enable the associated error/alarm. Reading this register returns the value of the mask bit.
0x33138 EE_EV3_LINK_MSK_SET_A — Event 3 Link Interrupt Source Mask Set Reg A
  fields as EE_EV2_LINK_MSK_SET_A
0x3313C EE_EV3_LINK_MSK_SET_B access not given — Event 3 Link Interrupt Source Mask Set Reg B
  fields as EE_EV2_LINK_MSK_SET_B
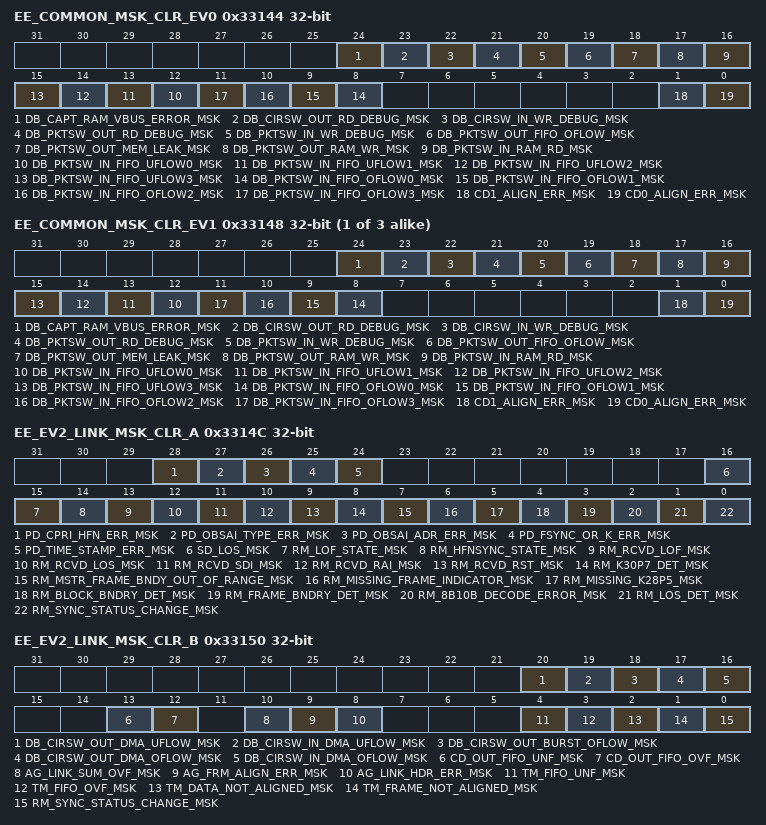
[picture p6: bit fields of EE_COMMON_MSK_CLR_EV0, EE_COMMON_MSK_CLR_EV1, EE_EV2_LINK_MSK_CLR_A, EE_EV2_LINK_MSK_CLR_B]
0x33144 EE_COMMON_MSK_CLR_EV0 — Event Enable 0 Common Interrupt Mask Clear Register
  [24] DB_CAPT_RAM_VBUS_ERROR_MSK rw — Mask for associated bit in the EE_LINK_COMMON_EV register. Writing this bit to a 1 clears the mask to 0 to disable the associated error/alarm. Reading this register returns the value of the mask bit.
  [23] DB_CIRSW_OUT_RD_DEBUG_MSK rw — Mask for associated bit in the EE_LINK_COMMON_EV register. Writing this bit to a 1 clears the mask to 0 to disable the associated error/alarm. Reading this register returns the value of the mask bit.
  [22] DB_CIRSW_IN_WR_DEBUG_MSK rw — Mask for associated bit in the EE_LINK_COMMON_EV register. Writing this bit to a 1 clears the mask to 0 to disable the associated error/alarm. Reading this register returns the value of the mask bit.
  [21] DB_PKTSW_OUT_RD_DEBUG_MSK rw — Mask for associated bit in the EE_LINK_COMMON_EV register. Writing this bit to a 1 clears the mask to 0 to disable the associated error/alarm. Reading this register returns the value of the mask bit.
  [20] DB_PKTSW_IN_WR_DEBUG_MSK rw — Mask for associated bit in the EE_LINK_COMMON_EV register. Writing this bit to a 1 clears the mask to 0 to disable the associated error/alarm. Reading this register returns the value of the mask bit.
  [19] DB_PKTSW_OUT_FIFO_OFLOW_MSK rw — Mask for associated bit in the EE_LINK_COMMON_EV register. Writing this bit to a 1 clears the mask to 0 to disable the associated error/alarm. Reading this register returns the value of the mask bit.
  [18] DB_PKTSW_OUT_MEM_LEAK_MSK rw — Mask for associated bit in the EE_LINK_COMMON_EV register. Writing this bit to a 1 clears the mask to 0 to disable the associated error/alarm. Reading this register returns the value of the mask bit.
  [17] DB_PKTSW_OUT_RAM_WR_MSK rw — Mask for associated bit in the EE_LINK_COMMON_EV register. Writing this bit to a 1 clears the mask to 0 to disable the associated error/alarm. Reading this register returns the value of the mask bit.
  [16] DB_PKTSW_IN_RAM_RD_MSK rw — Mask for associated bit in the EE_LINK_COMMON_EV register. Writing this bit to a 1 clears the mask to 0 to disable the associated error/alarm. Reading this register returns the value of the mask bit.
  [n+12] DB_PKTSW_IN_FIFO_UFLOW{n}_MSK rw (n=0..3) — Mask for associated bit in the EE_LINK_COMMON_EV register. Writing this bit to a 1 clears the mask to 0 to disable the associated error/alarm. Reading this register returns the value of the mask bit.
  [n+8] DB_PKTSW_IN_FIFO_OFLOW{n}_MSK rw (n=0..3) — Mask for associated bit in the EE_LINK_COMMON_EV register. Writing this bit to a 1 clears the mask to 0 to disable the associated error/alarm. Reading this register returns the value of the mask bit.
  [1] CD1_ALIGN_ERR_MSK rw — Mask for associated bit in the EE_LINK_COMMON_EV register. Writing this bit to a 1 clears the mask to 0 to disable the associated error/alarm. Reading this register returns the value of the mask bit.
  [0] CD0_ALIGN_ERR_MSK rw — Mask for associated bit in the EE_LINK_COMMON_EV register. Writing this bit to a 1 clears the mask to 0 to disable the associated error/alarm. Reading this register returns the value of the mask bit.
{0x3313C+0xC*i} EE_COMMON_MSK_CLR_EV{i} (i=1..3) — Event Enable {i} Common Interrupt Mask Clear Register
  fields as EE_COMMON_MSK_CLR_EV0
0x3314C EE_EV2_LINK_MSK_CLR_A — Event 2 Link Interrupt Mask Clear Reg A
  fields as EE_EV0_LINK_MSK_CLR_A0
0x33150 EE_EV2_LINK_MSK_CLR_B — Event 2 Link Interrupt Mask Clear Reg B
  fields as EE_EV0_LINK_MSK_CLR_B0
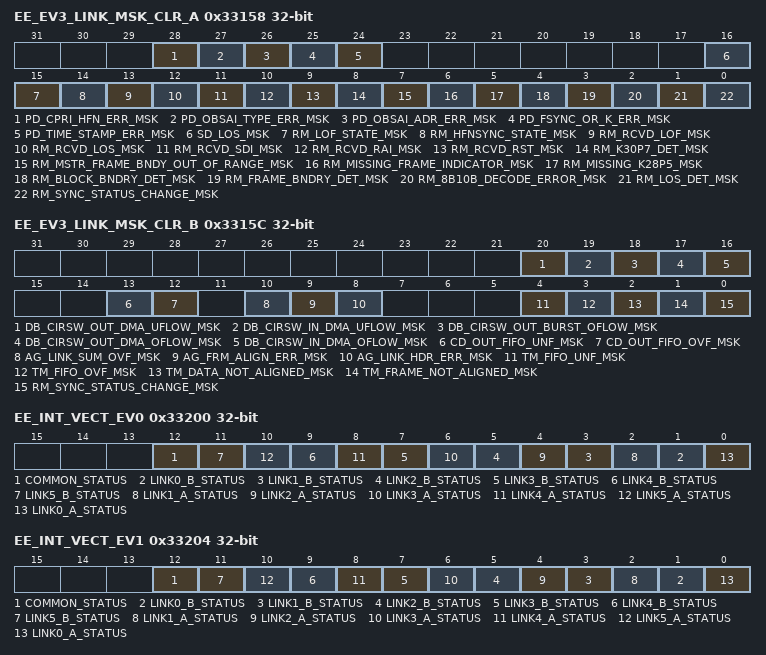
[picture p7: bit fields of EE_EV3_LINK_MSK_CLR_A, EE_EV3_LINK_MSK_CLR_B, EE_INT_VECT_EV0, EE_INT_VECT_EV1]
0x33158 EE_EV3_LINK_MSK_CLR_A — Event 3 Link Interrupt Mask Clear Reg A
  fields as EE_EV0_LINK_MSK_CLR_A0
0x3315C EE_EV3_LINK_MSK_CLR_B — Event 3 Link Interrupt Mask Clear Reg B
  fields as EE_EV0_LINK_MSK_CLR_B0
0x33200 EE_INT_VECT_EV0 ro — Event Enable Interrupt Vector Register for AI_EVENT0
  [12] COMMON_STATUS — Status for EE_COMMON_IMS_EV0 register:
  [2n+1] LINK{n}_B_STATUS (n=0..5) — Status for EE_LINK{n}_IMS_B_EV0 register:
  [2n] LINK{n}_A_STATUS (n=1..5) — Status for EE_LINK{n}_IMS_A_EV0 register:
  [0] LINK0_A_STATUS — Status for EE_LINK0_IMS_A_EV0 register:
    0=NO_ERRORS (0 - NO ACTIVE ERROR/ALARM IN REGISTER); 1=ERRORS (1 - 1 OR MORE ACTIVE ERRORS/ALARMS IN REGISTER)
0x33204 EE_INT_VECT_EV1 ro — Event Enable Interrupt Vector Register for AI_EVENT1
  [12] COMMON_STATUS — Status for EE_COMMON_IMS_EV1 register:
  [2n+1] LINK{n}_B_STATUS (n=0..5) — Status for EE_LINK{n}_IMS_B_EV1 register:
  [2n] LINK{n}_A_STATUS (n=1..5) — Status for EE_LINK{n}_IMS_A_EV1 register:
  [0] LINK0_A_STATUS — Status for EE_LINK0_IMS_A_EV1 register:
    values as EE_INT_VECT_EV0.LINK0_A_STATUS
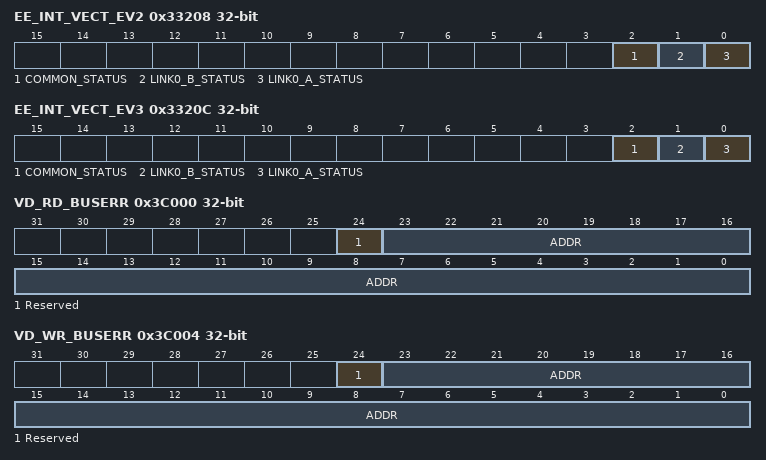
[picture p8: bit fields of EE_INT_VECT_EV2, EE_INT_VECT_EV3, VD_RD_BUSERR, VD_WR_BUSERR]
0x33208 EE_INT_VECT_EV2 ro — Event Enable Interrupt Vector Register for AI_EVENT2
  [2] COMMON_STATUS — Status for EE_COMMON_EV2 register:
  [1] LINK0_B_STATUS — Status for EE_LINK1_IMS_B_EV2 register:
  [0] LINK0_A_STATUS — Status for EE_LINK_IMS_A_EV2 register:
    values as EE_INT_VECT_EV0.LINK0_A_STATUS
0x3320C EE_INT_VECT_EV3 ro — Event Enable Interrupt Vector Register for AI_EVENT3
  [2] COMMON_STATUS — Status for EE_COMMON_EV3 register:
  [1] LINK0_B_STATUS — Status for EE_LINK1_IMS_B_EV3 register:
  [0] LINK0_A_STATUS — Status for EE_LINK_IMS_A_EV3 register:
    values as EE_INT_VECT_EV0.LINK0_A_STATUS
0x3C000 VD_RD_BUSERR access not given — VBUSP DMA Read Bus Interface Status Registers
  [24] Reserved — (access N)
  [23:0] ADDR rw — VBUSP configuration bus address that resulted in a bus error
0x3C004 VD_WR_BUSERR access not given — VBUSP DMA Write Bus Interface Status Registers
  fields as VD_RD_BUSERR
